# pmac_acm_secure register map
Vendor: Texas Instruments
Peripheral module from a debugger description file (folder CC35X1E).
Registers are 32-bit, access per field, reset 0x0 unless marked. A register's access mark holds for its fields unless they carry their own. Offsets are as the file gives them; lines under a group give offsets from that group; [hi:lo] are bit positions; {n}, {i} and the like mark numbered series; 'fields as' and 'values as' point back to an identical list; <NAME> marks a mode.

## pmac_acm_secure
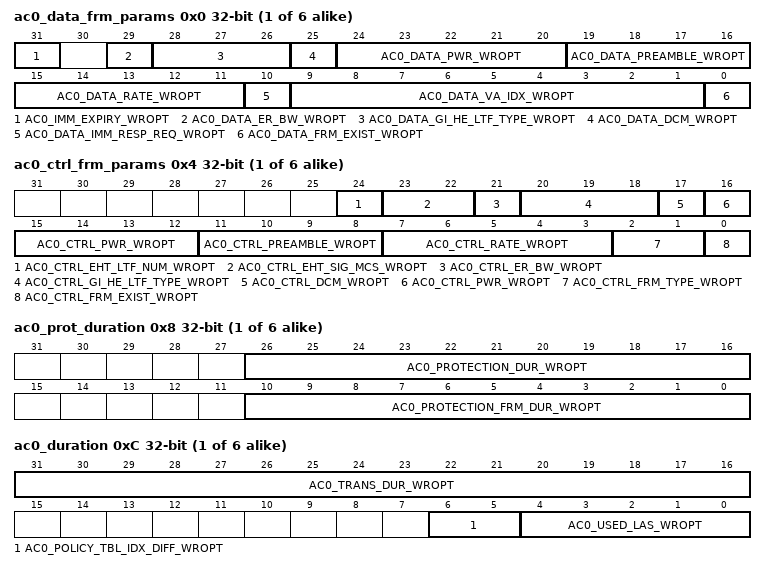
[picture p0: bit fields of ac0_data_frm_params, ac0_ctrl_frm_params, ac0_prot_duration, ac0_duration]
{0x0+0x30*i} ac{i}_data_frm_params (i=0..5) — current data frame params as set by the tx candidate.
  [31] AC{i}_IMM_EXPIRY_WROPT rw
  [29] AC{i}_DATA_ER_BW_WROPT rw
  [28:26] AC{i}_DATA_GI_HE_LTF_TYPE_WROPT rw
  [25] AC{i}_DATA_DCM_WROPT rw
  [24:20] AC{i}_DATA_PWR_WROPT rw — data frame power.
  [19:16] AC{i}_DATA_PREAMBLE_WROPT rw — data frame preamble. phy coding.
  [15:11] AC{i}_DATA_RATE_WROPT rw — data frame rate. pmac coding (not PHY coding)
  [10] AC{i}_DATA_IMM_RESP_REQ_WROPT rw — Immediate response is expected.
  [9:1] AC{i}_DATA_VA_IDX_WROPT rw — data frame's Virtual address index (frame at the head of the queue)
  [0] AC{i}_DATA_FRM_EXIST_WROPT rw — indication that the data AC regs are of a valid frame. asserte by candidate.
{0x4+0x30*i} ac{i}_ctrl_frm_params (i=0..5)
  [24] AC{i}_CTRL_EHT_LTF_NUM_WROPT rw
  [23:22] AC{i}_CTRL_EHT_SIG_MCS_WROPT rw
  [21] AC{i}_CTRL_ER_BW_WROPT rw
  [20:18] AC{i}_CTRL_GI_HE_LTF_TYPE_WROPT rw
  [17] AC{i}_CTRL_DCM_WROPT rw
  [16:12] AC{i}_CTRL_PWR_WROPT rw — control frame power.
  [11:8] AC{i}_CTRL_PREAMBLE_WROPT rw — control frame preamble (phy coding)
  [7:3] AC{i}_CTRL_RATE_WROPT rw — control frame rate. pmac coding (not PHY coding)
  [2:1] AC{i}_CTRL_FRM_TYPE_WROPT rw — control frame type: 0 - RTS, 1 - CTS, 2 - CF_END
  [0] AC{i}_CTRL_FRM_EXIST_WROPT rw — control frame exist - for RTS/CTS, if this bit is asserted, current transmission will be of the protection frame. for cf_end, transmission depands on remaining time and data frame existence.
{0x8+0x30*i} ac{i}_prot_duration (i=0..5)
  [26:16] AC{i}_PROTECTION_DUR_WROPT rw — entire protection duration CTS+SIFS or RTS+SIFS+CTS+SIFS. field is ignored in burst case.
  [10:0] AC{i}_PROTECTION_FRM_DUR_WROPT rw — protection frame duration - CTS, RTS or CF_END
{0xC+0x30*i} ac{i}_duration (i=0..5)
  [31:16] AC{i}_TRANS_DUR_WROPT rw — total transaction duration - protection + data frame and Imm response
  [6:5] AC{i}_POLICY_TBL_IDX_DIFF_WROPT rw — Indication on wither LAS state was overriden by get_rate nad wither to easier or harder state 00 - same state 01 - easier state 10 - harder state
  [4:0] AC{i}_USED_LAS_WROPT rw — Used LAS (Link adaptation state).
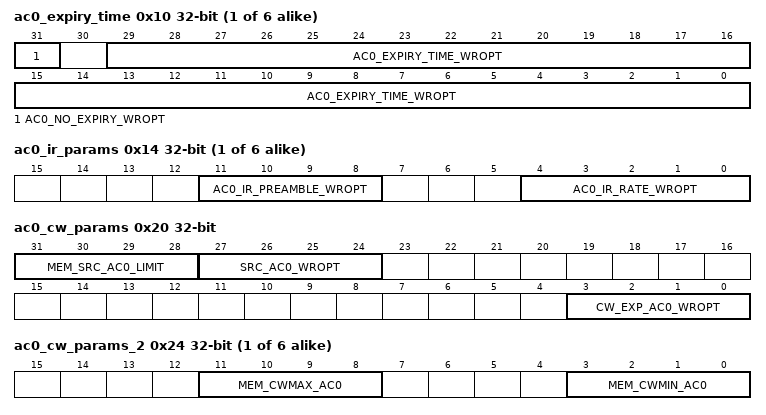
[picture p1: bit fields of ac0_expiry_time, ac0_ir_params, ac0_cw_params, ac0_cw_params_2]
{0x10+0x30*i} ac{i}_expiry_time (i=0..5)
  [31] AC{i}_NO_EXPIRY_WROPT rw
  [29:0] AC{i}_EXPIRY_TIME_WROPT rw — expiry time in micro seconds
{0x14+0x30*i} ac{i}_ir_params (i=0..5)
  [11:8] AC{i}_IR_PREAMBLE_WROPT rw — Imm response preamble (PHY coding)
  [4:0] AC{i}_IR_RATE_WROPT rw — Imm response rate (pmac coding)
0x20 ac0_cw_params reset not defined
  [31:28] MEM_SRC_AC0_LIMIT rw — station retries counter limit. src clears on values greater then this limit.
  [27:24] SRC_AC0_WROPT rw — station retries counter.
  [3:0] CW_EXP_AC0_WROPT rw — CW exponent for AC0
{0x24+0x30*i} ac{i}_cw_params_2 reset not defined (i=0..5)
  [11:8] MEM_CWMAX_AC{i} rw — cw max exponent
  [3:0] MEM_CWMIN_AC{i} rw — CW min exponent
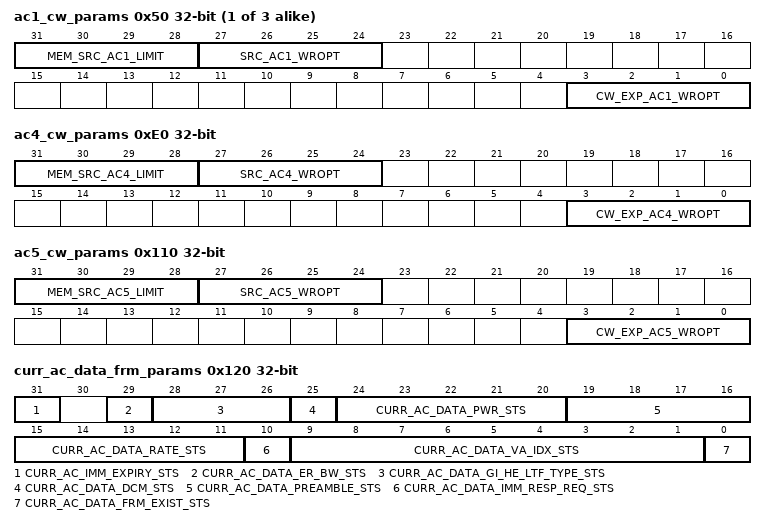
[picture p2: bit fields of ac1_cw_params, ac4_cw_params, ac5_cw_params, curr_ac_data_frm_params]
{0x20+0x30*i} ac{i}_cw_params reset not defined (i=1..3)
  [31:28] MEM_SRC_AC{i}_LIMIT rw
  [27:24] SRC_AC{i}_WROPT rw — station retries counter
  [3:0] CW_EXP_AC{i}_WROPT rw — CW exponent for AC{i}
0xE0 ac4_cw_params reset not defined
  [31:28] MEM_SRC_AC4_LIMIT rw
  [27:24] SRC_AC4_WROPT rw — station retries coutner
  [3:0] CW_EXP_AC4_WROPT rw — CW exponent for AC4
0x110 ac5_cw_params reset not defined
  [31:28] MEM_SRC_AC5_LIMIT rw
  [27:24] SRC_AC5_WROPT rw — station retries counter
  [3:0] CW_EXP_AC5_WROPT rw — CW mask for AC5
0x120 curr_ac_data_frm_params ro — current data frame params as set by the tx candidate.
  [31] CURR_AC_IMM_EXPIRY_STS
  [29] CURR_AC_DATA_ER_BW_STS
  [28:26] CURR_AC_DATA_GI_HE_LTF_TYPE_STS
  [25] CURR_AC_DATA_DCM_STS
  [24:20] CURR_AC_DATA_PWR_STS — data frame power.
  [19:16] CURR_AC_DATA_PREAMBLE_STS — data frame preamble. phy coding.
  [15:11] CURR_AC_DATA_RATE_STS — data frame rate. pmac coding (not PHY coding)
  [10] CURR_AC_DATA_IMM_RESP_REQ_STS — Immediate response is expected.
  [9:1] CURR_AC_DATA_VA_IDX_STS — data frame's Virtual address index (frame at the head of the queue)
  [0] CURR_AC_DATA_FRM_EXIST_STS — indication that the data AC regs are of a valid frame. asserte by candidate.
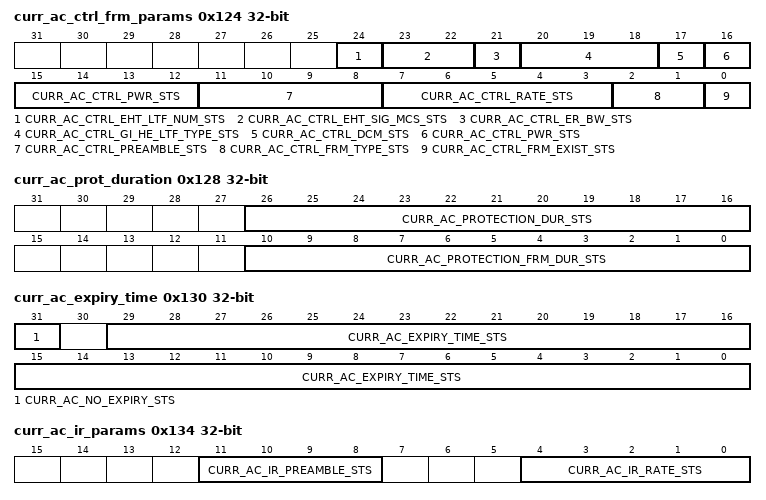
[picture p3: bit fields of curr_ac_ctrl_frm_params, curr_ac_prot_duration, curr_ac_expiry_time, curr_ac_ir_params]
0x124 curr_ac_ctrl_frm_params ro
  [24] CURR_AC_CTRL_EHT_LTF_NUM_STS
  [23:22] CURR_AC_CTRL_EHT_SIG_MCS_STS
  [21] CURR_AC_CTRL_ER_BW_STS
  [20:18] CURR_AC_CTRL_GI_HE_LTF_TYPE_STS
  [17] CURR_AC_CTRL_DCM_STS — data frame DCM (Dual Code Modulation).
  [16:12] CURR_AC_CTRL_PWR_STS — control frame power.
  [11:8] CURR_AC_CTRL_PREAMBLE_STS — control frame preamble (phy coding)
  [7:3] CURR_AC_CTRL_RATE_STS — control frame rate. pmac coding (not PHY coding)
  [2:1] CURR_AC_CTRL_FRM_TYPE_STS — control frame type: 0 - RTS, 1 - CTS, 2 - CF_END
  [0] CURR_AC_CTRL_FRM_EXIST_STS — control frame exist - for RTS/CTS, if this bit is asserted, current transmission will be of the protection frame. for cf_end, transmission depands on remaining time and data frame existence.
0x128 curr_ac_prot_duration ro
  [26:16] CURR_AC_PROTECTION_DUR_STS — entire protection duration CTS+SIFS or RTS+SIFS+CTS+SIFS. field is ignored in burst case.
  [10:0] CURR_AC_PROTECTION_FRM_DUR_STS — protection frame duration - CTS, RTS or CF_END
0x12C curr_ac_duration ro
  [31:16] CURR_AC_TRANS_DUR_STS — total transaction duration - protection + data frame and Imm response
0x130 curr_ac_expiry_time ro
  [31] CURR_AC_NO_EXPIRY_STS
  [29:0] CURR_AC_EXPIRY_TIME_STS — expiry time in micro seconds
0x134 curr_ac_ir_params ro
  [11:8] CURR_AC_IR_PREAMBLE_STS — Imm response preamble (PHY coding)
  [4:0] CURR_AC_IR_RATE_STS — Imm response rate (pmac coding)
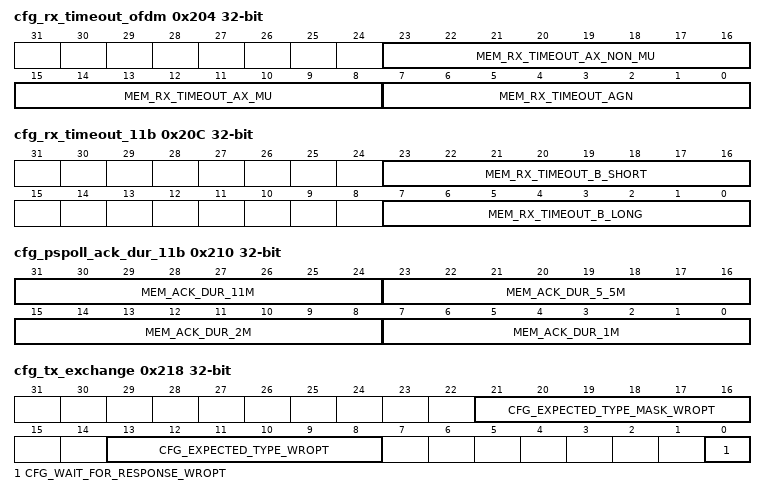
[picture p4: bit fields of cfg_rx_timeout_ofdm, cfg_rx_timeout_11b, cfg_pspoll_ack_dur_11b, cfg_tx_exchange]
0x204 cfg_rx_timeout_ofdm
  [23:16] MEM_RX_TIMEOUT_AX_NON_MU rw — Rx timeout for HE non MU use cases (HE_SU, HE-ER-SU, HE-TB).
  [15:8] MEM_RX_TIMEOUT_AX_MU rw — Rx timeout for HE_MU use case.
  [7:0] MEM_RX_TIMEOUT_AGN rw — Rx timeout for legacy, HT-MM and HT-GF use cases.
0x20C cfg_rx_timeout_11b
  [23:16] MEM_RX_TIMEOUT_B_SHORT rw — Rx timeout for 11b short use case.
  [7:0] MEM_RX_TIMEOUT_B_LONG rw — Rx timeout for 11b long use case.
0x210 cfg_pspoll_ack_dur_11b rw reset not defined — claculations do not include the preamble - it is set by HW according to current incoming frame.
  [31:24] MEM_ACK_DUR_11M — sifs + ack duration for 11mbps
  [23:16] MEM_ACK_DUR_5_5M — sifs + ack duration for 5.5mbps
  [15:8] MEM_ACK_DUR_2M — sifs + ack duration for 2mbps
  [7:0] MEM_ACK_DUR_1M — sifs + ack duration for 1mbps
0x214 cfg_pspoll_ack_dur_ofdm reset not defined
  [7:0] MEM_ACK_DUR_6_OFDM rw — sifs + ack duration at 6mbps
0x218 cfg_tx_exchange
  [21:16] CFG_EXPECTED_TYPE_MASK_WROPT rw, [13:8] CFG_EXPECTED_TYPE_WROPT rw, [0] CFG_WAIT_FOR_RESPONSE_WROPT rw
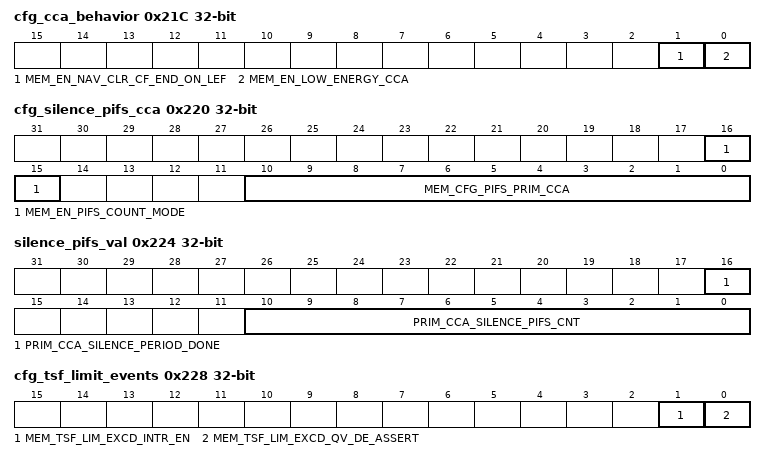
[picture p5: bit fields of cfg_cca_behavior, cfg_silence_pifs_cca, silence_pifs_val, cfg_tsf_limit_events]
0x21C cfg_cca_behavior reset not defined
  [1] MEM_EN_NAV_CLR_CF_END_ON_LEF rw — when set, low energy cf_end frame clears the NAV . when cleared lef cf_end is ignored with regards to NAV like all rx lef frames.
  [0] MEM_EN_LOW_ENERGY_CCA rw — when set, if qual_cca is high while phy_cca is low, force qual_cca to as well and use RIP to prevent starting tranmission during currently received rx
0x220 cfg_silence_pifs_cca reset not defined — PIFS counter for CCA
  [16:15] MEM_EN_PIFS_COUNT_MODE rw — 00: disabled. force the status to silence period done. 01: single count. counter counts until cca_idle time and locks until disabled. 10: continuous count cca aware- clear the timer on every cca_busy 11: continuous count cca un-aware - on cca fall, count without stopping until expired.
  [10:0] MEM_CFG_PIFS_PRIM_CCA rw — PIFS duration for primary pifs counter. count is in 20MHz resolution (50ns)
0x224 silence_pifs_val ro
  [16] PRIM_CCA_SILENCE_PERIOD_DONE
  [10:0] PRIM_CCA_SILENCE_PIFS_CNT — current value of the silnce pifs counter
0x228 cfg_tsf_limit_events
  [1] MEM_TSF_LIM_EXCD_INTR_EN rw — when set, if any AC's tsf limit was crossed, assert an IRQ to SW.
  [0] MEM_TSF_LIM_EXCD_QV_DE_ASSERT rw — when set, it any AC's TSF limit was crossed, create a qv de_assert request for that AC
0x22C tx_nav
  [14:0] TX_NAV_WROPT rw — tx nav counter. set by HW to 'duration' on tx_trigger. cleared when frames markd by SW to clear the tx_nav. counts in usec resolution
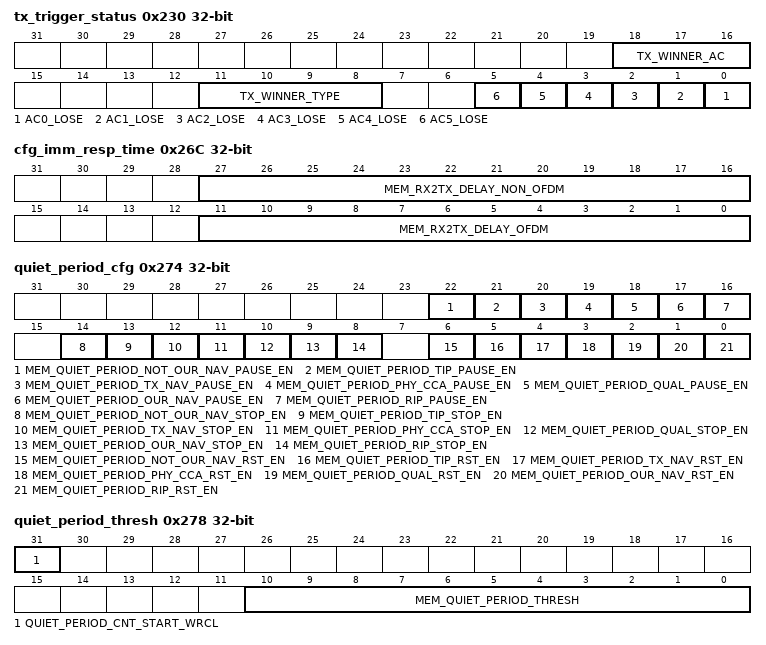
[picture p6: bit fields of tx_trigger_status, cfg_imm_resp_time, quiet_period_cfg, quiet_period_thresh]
0x230 tx_trigger_status ro
  [18:16] TX_WINNER_AC — latched value of the last AC winner (AC0-AC5). this may be used to understand in burst/cf_end which is the originating AC
  [11:8] TX_WINNER_TYPE — 0: EDCA 1: Immidiate response 2: Burst 3: Cf_end after rx time out 4: Trigger-Based data 5: Trigger-Based immidiate response 6: Trigger-Based report
  [n] AC{n}_LOSE (n=0..5) — ac lost in EDCA internal collision
0x234 tx_delay_cnt reset not defined
  [11:0] MEM_TXDELAY_CNT rw
{0x238+8i} tsf_start_ac{i} rw (i=0..5) — The access mechanism is active when TSF bigger then TSF START. In case that TSF start is zero, then the above condition is true, so the access mechanim is active.
  [31:0] MEM_TSF_START_VALUE_AC{i}
{0x23C+8i} tsf_end_ac{i} rw (i=0..5) — It contains the low bits of the END TSF value. The access mechanism is active when TSF smaller then TSF END. In case that TSF start is zero, then the above condition is true, so the access mechanim is active.
  [31:0] MEM_TSF_END_VALUE_AC{i}
0x268 cfg_burst_thresh reset not defined
  [6:0] MEM_ENOUGH_TIME_CF_END_EXT rw — number of usec to add to the 'enough time for cf_end' indication from access to tx manager. this allows to avoid transmitting cf_end if txop is almost exhausted anyway.
0x26C cfg_imm_resp_time reset not defined
  [27:16] MEM_RX2TX_DELAY_NON_OFDM rw — delay in 40MHz cycles to count for imm response after rx (sifs) for 11b rx
  [11:0] MEM_RX2TX_DELAY_OFDM rw — delay in 40MHz cycles to count for imm response after rx (sifs) for ofdm rx
0x270 access_spare_reg rw reset 0xFFFF
  [31:0] MEM_ACCESS_SPARE_REG
0x274 quiet_period_cfg
  [22] MEM_QUIET_PERIOD_NOT_OUR_NAV_PAUSE_EN rw — when set, counter is paused on NAV
  [21] MEM_QUIET_PERIOD_TIP_PAUSE_EN rw — when set, counter is paused on TIP | TXIP
  [20] MEM_QUIET_PERIOD_TX_NAV_PAUSE_EN rw — when set, counter is paused on TX_NAV
  [19] MEM_QUIET_PERIOD_PHY_CCA_PAUSE_EN rw — when set, counter is paused on PHY_CCA (from phy, no MAC overrides)
  [18] MEM_QUIET_PERIOD_QUAL_PAUSE_EN rw — when set, counter is paused on QUAL_CCA (from phy, no MAC overrides)
  [17] MEM_QUIET_PERIOD_OUR_NAV_PAUSE_EN rw — when set, counter is paused on NAV
  [16] MEM_QUIET_PERIOD_RIP_PAUSE_EN rw — when set, counter is paused on RIP | RXIP
  [14] MEM_QUIET_PERIOD_NOT_OUR_NAV_STOP_EN rw — when set, counter is paused on NAV
  [13] MEM_QUIET_PERIOD_TIP_STOP_EN rw — when set, counter is paused on TIP | TXIP
  [12] MEM_QUIET_PERIOD_TX_NAV_STOP_EN rw — when set, counter is paused on TX_NAV
  [11] MEM_QUIET_PERIOD_PHY_CCA_STOP_EN rw — when set, counter is paused on PHY_CCA (from phy, no MAC overrides)
  [10] MEM_QUIET_PERIOD_QUAL_STOP_EN rw — when set, counter is paused on QUAL_CCA (from phy, no MAC overrides)
  [9] MEM_QUIET_PERIOD_OUR_NAV_STOP_EN rw — when set, counter is paused on NAV
  [8] MEM_QUIET_PERIOD_RIP_STOP_EN rw — when set, counter is paused on RIP | RXIP
  [6] MEM_QUIET_PERIOD_NOT_OUR_NAV_RST_EN rw — when set, counter is reset on NAV
  [5] MEM_QUIET_PERIOD_TIP_RST_EN rw — when set, counter is reset on TIP | TXIP
  [4] MEM_QUIET_PERIOD_TX_NAV_RST_EN rw — when set, counter is reset on TX_NAV
  [3] MEM_QUIET_PERIOD_PHY_CCA_RST_EN rw — when set, counter is reset on PHY_CCA (from phy, no MAC overrides)
  [2] MEM_QUIET_PERIOD_QUAL_RST_EN rw — when set, counter is reset on QUAL_CCA (from phy, no MAC overrides)
  [1] MEM_QUIET_PERIOD_OUR_NAV_RST_EN rw — when set, counter is reset on NAV
  [0] MEM_QUIET_PERIOD_RIP_RST_EN rw — when set, counter is reset on RIP | RXIP
0x278 quiet_period_thresh
  [31] QUIET_PERIOD_CNT_START_WRCL wo — counter kick, wr only/self clearing
  [10:0] MEM_QUIET_PERIOD_THRESH rw — counter threshold in 32usec resolution. Threshold should not be modified during counter operation. in order to change, counter need to be halted and re-configured
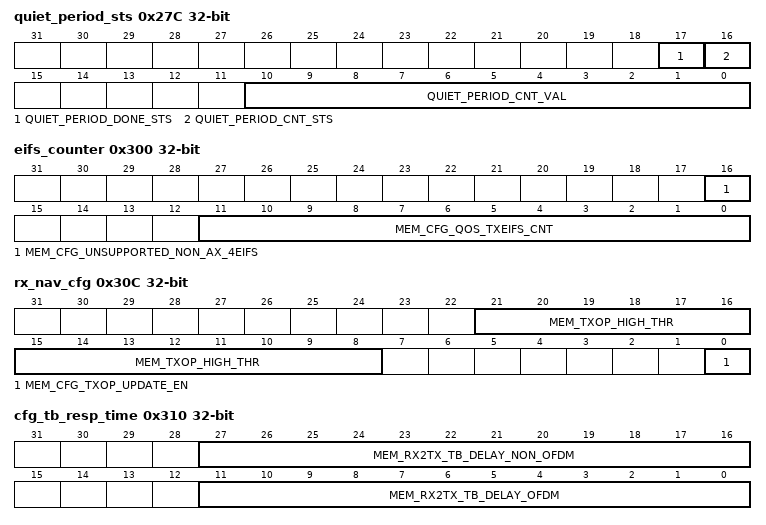
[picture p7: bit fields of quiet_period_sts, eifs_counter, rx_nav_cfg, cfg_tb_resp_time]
0x27C quiet_period_sts ro
  [17] QUIET_PERIOD_DONE_STS — when read as 1, counter has already expired and asserted the interrupt.
  [16] QUIET_PERIOD_CNT_STS — when read as 1, counter is during count (even if paused/cleared by the HW)
  [10:0] QUIET_PERIOD_CNT_VAL — current counter value
0x280 quiet_period_cnt_stop
  [0] QUIET_PERIOD_CNT_STOP_WRCL wo — writing 1 to this bit will stop the counter.
{0x284+0x14*i} backoff_timer_ac{i}_reg (i=0..3) — Back-off counter for AC {i} (BACKOFF_TIMER_AC{i}_REG)
  [15:0] MEM_BACKOFF_TIMER_AC{i}_WROPT rw — Random back-off timer. Latch with random value between 0 to CW[AC] count down to 0 every time AIFS[AC] timeout out and slot timer reaches zero.
{0x288+0x14*i} copy_backoff_timer_ac{i}_reg (i=0..3) — Copy back-off timer AC{i} (COPY_BACKOFF_TIMER_AC{i}_REG)
  [15:0] MEM_COPY_BACKOFF_TIMER_AC{i}_WROPT rw — Random back-off timer for AC{i}. Used for interference fix. Latch stores back-off value for AC{i} when input/tx CCA indicate medium busy.
0x28C rng_ac0 rw reset 0xAAAA5555
  [31:0] MEM_RNG_AC0_WROPT — Initial value for Ramdom Number Generator for this AC
0x290 ac0_tx_aifs_cfg_reg reset 0x3D03D — Slot Count (ACM_IFS_CFG1)
  [11:0] MEM_CFG_TXAIFS0_CNT rw — AC0 AIFS counter size in micro seconds
{0x294+0x14*i} ac{i}_tx_aifs_timer_reg (i=0..5) — Current value of AIFS timer for this ac
  [11:0] MEM_TXAIFS{i}_TIMER_WROPT rw — Current value of AIFS timer in usec.;It_s a up counter. this value get compared with ACM_TX_AIFS[n] to start back-off countdown.
0x2A0 rng_ac1 rw reset 0xAA55AA55
  [31:0] MEM_RNG_AC1_WROPT — Initial value for Ramdom Number Generator for this AC
0x2A4 ac1_tx_aifs_cfg_reg reset 0x1D01D — Transmit AIFS1 timer (AC1_TX_AIFS_CFG_REG)
  [11:0] MEM_CFG_TXAIFS1_CNT rw — TxAIFS1/EIFS timer in usec. ;Configured with the value obtained from EDCA parameter from QAP. No byte access must write entire field once.
0x2B4 rng_ac2 rw reset 0x55AA55AA
  [31:0] MEM_RNG_AC2_WROPT — Initial value for Ramdom Number Generator for this AC
0x2B8 ac2_tx_aifs_cfg_reg — Transmit AIFS2 timer (AC2_TX_AIFS_CFG_REG)
  [11:0] MEM_CFG_TXAIFS2_CNT rw — TxAIFS2/EIFS timer in usec. ;Configured with the value obtained from EDCA parameter from QAP.;No byte access must write entire field once.
0x2C8 rng_ac3 rw reset 0x5A5A5A5A
  [31:0] MEM_RNG_AC3_WROPT — Initial value for Ramdom Number Generator for this AC
0x2CC ac3_tx_aifs_cfg_reg reset 0x15015 — Transmit AIFS3 timer (AC3_TX_AIFS_CFG_REG)
  [11:0] MEM_CFG_TXAIFS3_CNT rw — TxAIFS3/EIFS timer in usec. ;Configured with the value obtained from EDCA parameter from QAP.;No byte access must write entire field once.
0x2D4 backoff_timer_ac4_reg
  [14:0] MEM_BACKOFF_TIMER_AC4_WROPT rw — Backoff for AC4 mechanism
0x2D8 copy_of_backoff_timer_ac4_reg
  [14:0] MEM_COPY_BACKOFF_TIMER_AC4_WROPT rw — copy Backoff for AC4 mechanism
0x2DC rng_ac4 rw reset 0xAAAA5555
  [31:0] MEM_RNG_AC4_WROPT — Initial value for Ramdom Number Generator for this AC4
0x2E0 ac4_tx_aifs_cfg_reg
  [11:0] MEM_CFG_TXAIFS4_CNT rw — aifs value for AC4
0x2E8 backoff_timer_ac5_reg
  [14:0] MEM_BACKOFF_TIMER_AC5_WROPT rw — Backoff for AC5 mechanism
0x2EC copy_of_backoff_timer_ac5_reg
  [14:0] MEM_COPY_BACKOFF_TIMER_AC5_WROPT rw — copy Backoff for AC4 mechanism
0x2F0 rng_ac5 rw reset 0xAAAA5555
  [31:0] MEM_RNG_AC5_WROPT — Initial value for Ramdom Number Generator for this AC5
0x2F4 ac5_tx_aifs_cfg_reg
  [11:0] MEM_CFG_TXAIFS5_CNT rw — aifs value for AC5
0x2FC acm_tx_eifs_timer_reg — Current value of EIFS counter (ACM_TX_EIFS_TIMER_REG)
  [11:0] MEM_TXEIFS_TIMER_WROPT rw — Current value of EIFS timer in usec.
0x300 eifs_counter — EIFS-DIFS value configuration for Meduim access backoff usage.
  [16] MEM_CFG_UNSUPPORTED_NON_AX_4EIFS rw — For: Received frames which are not of AX type, and unsupported (meaning there is not a valid PHY Header): if '1' (default) - set EIFS timer if '0' - don't set EIFS timer
  [11:0] MEM_CFG_QOS_TXEIFS_CNT rw — EIFS counter configuration value
0x304 our_nav — Network allocation Vector (NAV)* (1) OUR NAV / INTRA BSS NAV
  [15:0] OUR_NAV_WROPT rw — Network allocation vector (virtual carrier sense). Loaded. cleared and decremented according to 802.11 spec. When non-zero. normal transmit operations will be prevented. (usec) ) (No byte access. must write as 16 bit register). our_bss: Protection from frames transmitted by STAs within its BSS, i.e., intra-BSS,
0x308 not_our_nav — Network allocation Vector (NAV)* (2) NOT OUR NAV / INTER BSS NAV / BASIC NAV
  [15:0] NOT_OUR_NAV_WROPT rw — Network allocation vector (virtual carrier sense). Loaded. cleared and decremented according to 802.11 spec. When non-zero. normal transmit operations will be prevented. (usec) ) (No byte access. must write as 16 bit register). Network allocation vector (virtual carrier sense). Loaded. cleared and decremented according to 802.11 spec. When non-zero. normal transmit operations will be prevented. (usec) ) (No byte access. must write as 16 bit register). not_our_bss: Avoid interference from frames transmitted by STAs in a neighboring BSS, i.e., inter-BSS.
0x30C rx_nav_cfg reset not defined — Configuration controls for dual NAVs feature
  [21:8] MEM_TXOP_HIGH_THR rw — If TXOP field is greater than this THR, don't update NAVs with TXOP
  [0] MEM_CFG_TXOP_UPDATE_EN rw — if ='0': Disable ability to update NAVs by TXOP field from PHY-Header
0x310 cfg_tb_resp_time reset not defined
  [27:16] MEM_RX2TX_TB_DELAY_NON_OFDM rw — delay in 40MHz cycles to count for response after trigger frame (sifs) for 11b rx
  [11:0] MEM_RX2TX_TB_DELAY_OFDM rw — delay in 40MHz cycles to count for response after trigger frame (sifs) for ofdm rx
0x314 cfg_tb_cs_time reset not defined
  [11:0] MEM_TB_CS_DELAY_CNT rw — Delay in 40MHz cycles to count when to start CS detection during SIFS period.
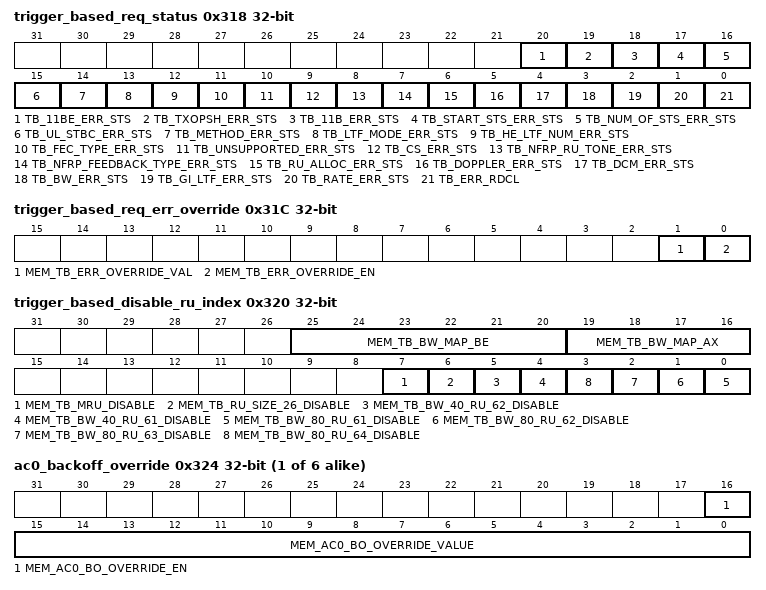
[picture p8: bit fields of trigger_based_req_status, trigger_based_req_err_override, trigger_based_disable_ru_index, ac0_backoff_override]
0x318 trigger_based_req_status ro reset not defined
  [20] TB_11BE_ERR_STS — Trigger-Based request with 11.BE (=EHT=WiFi7) packet error. Clear on TB_ERR_RDCL read.
  [19] TB_TXOPSH_ERR_STS — Trigger-Based MU-RTS TXOP-Sharing request error. Clear on TB_ERR_RDCL read.
  [18] TB_11B_ERR_STS — Trigger-Based request with 11B packet error. Clear on TB_ERR_RDCL read.
  [17] TB_START_STS_ERR_STS — Trigger-Based request with Starting SS error. Clear on TB_ERR_RDCL read.
  [16] TB_NUM_OF_STS_ERR_STS — Trigger-Based request with Numer of SS error. Clear on TB_ERR_RDCL read.
  [15] TB_UL_STBC_ERR_STS — Trigger-Based request with STBC error. Clear on TB_ERR_RDCL read.
  [14] TB_METHOD_ERR_STS — Trigger-Based request with TB method error. Clear on TB_ERR_RDCL read.
  [13] TB_LTF_MODE_ERR_STS — Trigger-Based request with LTF Mode error. Clear on TB_ERR_RDCL read.
  [12] TB_HE_LTF_NUM_ERR_STS — Trigger-Based request with HE LTF NUM error. Clear on TB_ERR_RDCL read.
  [11] TB_FEC_TYPE_ERR_STS — Trigger-Based request with FEC type error. Clear on TB_ERR_RDCL read.
  [10] TB_UNSUPPORTED_ERR_STS — Trigger-Based request with unsupported type error. Clear on TB_ERR_RDCL read. The list of unsupported trigger types is determined by TRIGGER_BASED_TYPE_MASK configuration.
  [9] TB_CS_ERR_STS — Trigger-Based request with CS error. Clear on TB_ERR_RDCL read.
  [8] TB_NFRP_RU_TONE_ERR_STS — NFRP Trigger-Based request with RU tone error. Clear on TB_ERR_RDCL read.
  [7] TB_NFRP_FEEDBACK_TYPE_ERR_STS — NFRP Trigger-Based request with feedback type error. Clear on TB_ERR_RDCL read.
  [6] TB_RU_ALLOC_ERR_STS — Trigger-Based request with RU allocation error. Clear on TB_ERR_RDCL read.
  [5] TB_DOPPLER_ERR_STS — Trigger-Based request with doppler error. Clear on TB_ERR_RDCL read.
  [4] TB_DCM_ERR_STS — Trigger-Based request with DCM error. Clear on TB_ERR_RDCL read.
  [3] TB_BW_ERR_STS — Trigger-Based request with bandwidth error. Clear on TB_ERR_RDCL read.
  [2] TB_GI_LTF_ERR_STS — Trigger-Based request with GI_LTF field error. Clear on TB_ERR_RDCL read.
  [1] TB_RATE_ERR_STS — Trigger-Based request with rate error. Clear on TB_ERR_RDCL read.
  [0] TB_ERR_RDCL — Trigger-Based request general error. Bits [8:1] holds the reason for the error. Clear on read.
0x31C trigger_based_req_err_override reset not defined
  [1] MEM_TB_ERR_OVERRIDE_VAL rw — Override value for Trigger-Based request error decision.
  [0] MEM_TB_ERR_OVERRIDE_EN rw — Bypass HW error decision for Trigger-Based request. The override value is set by MEM_TB_ERR_OVERRIDE_VAL register
0x320 trigger_based_disable_ru_index reset not defined — Disable RU index 61-64 support Disable RU Size of 26 option Disable MRU as default option TB_BW MAPS for AX and BW
  [25:20] MEM_TB_BW_MAP_BE rw — TB_BW MAP to define which BW is Allowed for BE (=EHT=WjFi7) bit[0] - 20/20MHz (Default Allowed) bit[1] - 20/40MHz (Default Not Allowed) bit[2] - 20/80MHz (Default Not Allowed) bit[3] - 20/160MHz (Default Not Allowed) bit[4] - 20/320MHz-1 (Default Not Allowed) bit[5] - 20/320MHz-2 (Default Not Allowed)
  [19:16] MEM_TB_BW_MAP_AX rw — TB_BW MAP to define wich BW is Allowed bit[0] - 20/20MHz (Default Allowed) bit[1] - 20/40MHz (Default Allowed) bit[2] - 20/80MHz (Default Allowed) bit[3] - 20/160MHz (Default Not Allowed)
  [7] MEM_TB_MRU_DISABLE rw — Disable EHT MRU TB type for all bandwidthes
  [6] MEM_TB_RU_SIZE_26_DISABLE rw — Disable RU Size 26 support in all bandwidthes
  [5] MEM_TB_BW_40_RU_62_DISABLE rw — Disable RU index 62 support in 40MHz bandwidth
  [4] MEM_TB_BW_40_RU_61_DISABLE rw — Disable RU index 61 support in 40MHz bandwidth
  [n-61] MEM_TB_BW_80_RU_{n}_DISABLE rw (n=61..64) — Disable RU index {n} support in 80MHz bandwidth
{0x324+4i} ac{i}_backoff_override reset not defined (i=0..5)
  [16] MEM_AC{i}_BO_OVERRIDE_EN rw — Enable AC{i} backoff override
  [15:0] MEM_AC{i}_BO_OVERRIDE_VALUE rw — AC{i} backoff override value
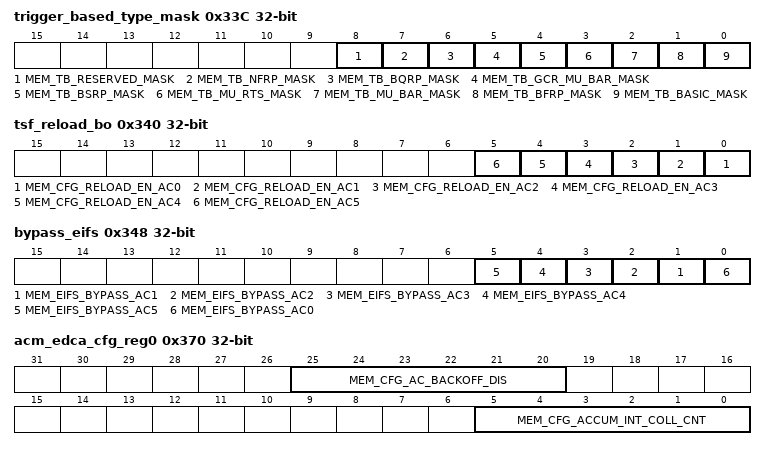
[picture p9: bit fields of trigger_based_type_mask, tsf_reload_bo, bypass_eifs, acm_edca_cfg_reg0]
0x33C trigger_based_type_mask reset not defined — Disable RU index 61-64 support
  [8] MEM_TB_RESERVED_MASK rw — Mask reserved trigger frame (types 8-15)
  [7] MEM_TB_NFRP_MASK rw — Mask NFRP (NDP Feedback Report Poll) trigger frame
  [6] MEM_TB_BQRP_MASK rw — Mask BQRP (Bandwidth Query Report Poll) trigger frame
  [5] MEM_TB_GCR_MU_BAR_MASK rw — Mask GCR MU-BAR trigger frame
  [4] MEM_TB_BSRP_MASK rw — Mask BSRP (Buffer Status Report Poll) trigger frame
  [3] MEM_TB_MU_RTS_MASK rw — Mask MU-RTS trigger frame
  [2] MEM_TB_MU_BAR_MASK rw — Mask MU-BAR trigger frame
  [1] MEM_TB_BFRP_MASK rw — Mask BFRP (Beamforming Report Poll) trigger frame
  [0] MEM_TB_BASIC_MASK rw — Mask basic trigger frame
0x340 tsf_reload_bo reset not defined
  [n] MEM_CFG_RELOAD_EN_AC{n} rw (n=0..5) — when set, when crossing TSF limit, BO will be reloaded
0x344 txsifs_timer reset 0xF00F0 — Transmit SIFS Timer (TXSIFS_TIMER)
  [11:0] TXSIFS_TIMER_WROPT rw — TxSIFS protocol timer. 0 if TxSIFS time expired. (usec) (No byte access. must write as 32 bit register).
0x348 bypass_eifs — when bit [n] is 1. the related ac ignore eifs: n=0: ac0 n=1: ac1 n=2: ac2 n=3: ac3 n=4: tsf1 n=5: tsf2
  [n] MEM_EIFS_BYPASS_AC{n} rw (n=1..5)
  [0] MEM_EIFS_BYPASS_AC0 rw — see above
0x34C slot_timer ro reset 0x320320 — Slot Timer (SLOT_TIMER)
  [11:0] SLOT_TIMER — Slot timer. Continuously counts down the slot time while the medium is idle and the TxDIFS/EIFS time has expired. (usec)
0x354 tsf_l ro — TSF Low (TSF_L)
  [31:0] TSF_31_0_WRDCL — Low 32 bits of station_s TSF timer. (usec) ) (No byte access. must write as 32 bit register).;This register must be read before _H
0x358 tsf_h rw — TSF High (TSF_H)
  [31:0] HOLD_REG_WROPT — High 32 bits of station_s TSF timer. (usec) ) (No byte access. must write as 32 bit register).;This register must be written to before _L
0x35C med_usage ro — Medium Usage (MED_USAGE)*
  [31:0] MED_USAGE_31_0_RDCL — Incremented every usec when medium is busy (physical or virtual carrier sense). Automatically cleared upon read.
0x360 med_usage_tm ro — Medium Usage Time (MED_USAGE_TM)
  [31:0] HOLD_REG_31_0 — Number of usec sense MED_USAGE was last read. (Note: These 2 registers can give a general feel for the utilization of the network. Must read MED_USAGE_TM prior to reading MED_USAGE.)
0x364 dtim_cnt — DTIM Counter (DTIM_CNT)
  [7:0] DTIM_CNT_WROPT rw — Current DTIM count for BSS. ) (No byte access. must write as 32-bit register).
0x368 prb_dly ro — Probe Delay Time (PRB_DLY)
  [9:0] PRB_DLY_TIMER — Current value of probe delay timer. Loaded with probe delay time upon clearing ENABLE [0] or ENABLE [1] or setting HW_DOZE. Prevents normal transmit until a frame is received or reaches zero.
0x36C cfg_acm — QOS Auto ACK Disable (CFG_ACM)
  [0] MEM_CFG_NAV_QOS_EN rw
0x370 acm_edca_cfg_reg0 — EDCA Configuration 0 (ACM_EDCA_CFG_REG0)
  [25:20] MEM_CFG_AC_BACKOFF_DIS rw — No back-off: if this bit is set do not follow back-off. start transmission after AIFS;Bit [23] _ for AC3;Bit [22] _ for AC2;Bit [21] _ for AC1;Bit [20] _ for AC0;OPTIONAL: Bits 23.22.21 must be left at default
  [5:0] MEM_CFG_ACCUM_INT_COLL_CNT rw — Accumulate internal collision count for AC.;[0] _ AC0;[1] _ AC1;[2] _ AC2;[3] _ AC3;when set internal collision count get accumulated and doesn_t get cleared when particular AC wins contention. For debug.;OPTIONAL: Must be left at default
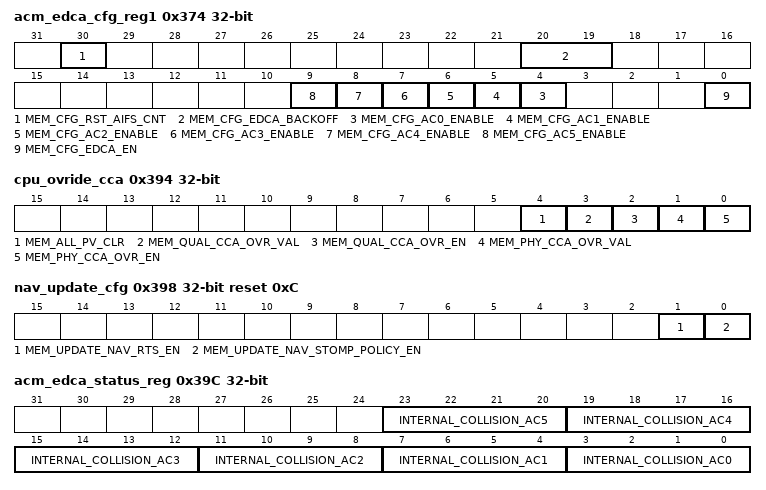
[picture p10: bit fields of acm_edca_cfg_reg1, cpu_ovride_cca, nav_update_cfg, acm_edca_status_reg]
0x374 acm_edca_cfg_reg1 reset not defined — EDCA Configuration 1 (ACM_EDCA_CFG_REG1)
  [30] MEM_CFG_RST_AIFS_CNT rw — Reset AIFS counter;Self-clearing but. If set clears AIFS timer.
  [20:19] MEM_CFG_EDCA_BACKOFF rw — EDCA back-off configuration;00 _ evoke back-off for all Acs when last transmission from any AC fails.;01 _ evoke back-off for other Acs only after expiry of NAV set by previously failed transmission.;1x _ evoke back-off for all AC only after TXOP (as configured in ACM_EDCA_TXOP_AC[n]) expires if last transmission fails.;OPTIONAL: Must be left at default
  [n+4] MEM_CFG_AC{n}_ENABLE rw (n=0..5) — Enable AC for transmission
  [0] MEM_CFG_EDCA_EN rw — EDCA enable: enable EDCA functionality
0x378 acm_ifs_cfg0 reset 0x190190 — SIFS Count (ACM_IFS_CFG0)
  [11:0] MEM_CFG_TXSIFS_CNT rw — Number of clock cycles in SIFS interval _ Radio RxTx turnaround time.
0x37C acm_ifs_cfg1 reset 0x4B04B0 — Slot time configuration (ACM_IFS_CFG1)
  [11:0] MEM_CFG_SLOT_CNT rw — Slot time size in pMAC clock cycles (60Mhz clock)
0x380 cca_busy ro — CCA Medium Busy (CCA_BUSY)
  [27:0] CCA_BUSY — Free running counter that counts the number of clock cycles with CCA_N from the PHY high (indicating busy). Cleared upon a read of CCA_BUSY_CLR.
0x384 cca_busy_clr access not given — CCA Medium Busy (CCA_BUSY_CLR)
  [27:0] CCA_BUSY_RDCL ro — Free running counter that counts the number of clock cycles with CCA_N from the PHY high (indicating busy). Cleared upon a read of CCA_BUSY_RDCL_CLR.
0x388 cca_idle ro — CCA Medium Idle (CCA_IDLE)
  [27:0] CCA_IDLE — Free running counter that counts the number of clock cycles with CCA_N from the PHY low (indicating idle). Cleared upon a read of CCA_IDLE_CLR.
0x38C cca_idle_clr access not given — CCA Medium Idle (CCA_IDLE_CLR)
  [27:0] CCA_IDLE_RDCL ro — Free running counter that counts the number of clock cycles with CCA_N from the PHY low (indicating idle). Cleared upon a read of CCA_IDLE_RDCL_CLR.
0x390 ccafall2rx_dly_timer reset 0x77 — delay from QUAL CCA fall.
  [3:0] MEM_CFG_CCAFALL2RX_DLY_YIMER rw — Start value for the counter that counts from QUAL CCA falling. this counter is used to decrement from the duration feild from the frame header to adjust for PHY internal delay.
0x394 cpu_ovride_cca — override signals from phy
  [4] MEM_ALL_PV_CLR rw — 0: all pv enabled. 1: mask all the PV status so they are all considered 0s.
  [3] MEM_QUAL_CCA_OVR_VAL rw — phy_plcp_valid override value
  [2] MEM_QUAL_CCA_OVR_EN rw — phy_plcp_valid override enable
  [1] MEM_PHY_CCA_OVR_VAL rw — phy_cca override value
  [0] MEM_PHY_CCA_OVR_EN rw — phy_cca override enable
0x398 nav_update_cfg reset 0xC (reset mask 0xFFFFFFFC) — NAV Update Policy Configuration (NAV_UPDATE_CFG)
  [1] MEM_UPDATE_NAV_RTS_EN rw, [0] MEM_UPDATE_NAV_STOMP_POLICY_EN rw
0x39C acm_edca_status_reg ro — EDCA status (ACM_EDCA_STATUS_REG)
  [4n+3:4n] INTERNAL_COLLISION_AC{n} (n=0..5) — Internal collision count for AC{n}. Get cleared when AC{n} wins
0x3A0 acm_post_cnxt_ld_time_reg reset 0x320190 — Post context load time (ACM_POST_CNXT_LD_TIME _REG)
  [12:0] MEM_CFG_POST_BACKOFF_TIMER rw — This timer start when back-off goes to 0. At backoff 0. context get loaded to PANG. At the expiry of this counter a transmit strobe is generated
0x3A4 rx_timeout_cnt access not given — RX timeout counter
  [7:0] RX_TOUT_DOWN_CNT ro — RX timeout counter status in usec
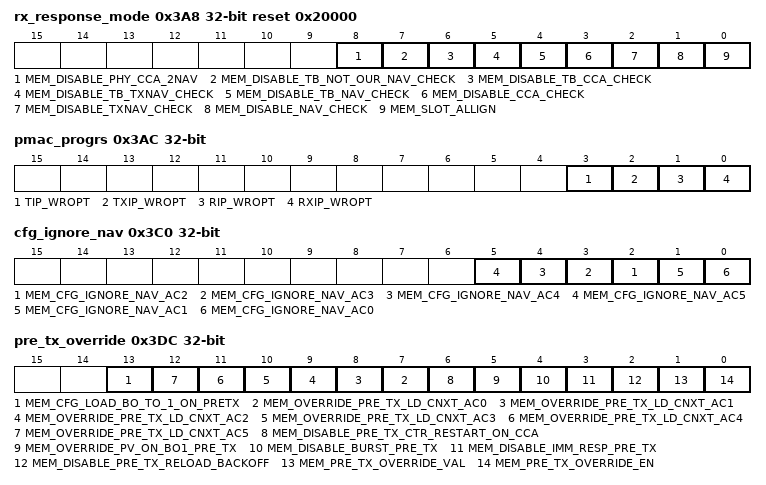
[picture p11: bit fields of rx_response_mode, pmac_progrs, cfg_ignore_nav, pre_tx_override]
0x3A8 rx_response_mode reset 0x20000 (reset mask 0xFFFFFE00) — Controls the option of the response frame timing
  [8] MEM_DISABLE_PHY_CCA_2NAV rw — Disable check of phy_cca to 'not_our_nav' One of the conditions to block TB response in addition to the 'cs_req' and NAV !=0, is that the air is cleared (this is from the 802.11 spec). If this bit is '1' - TB response is not depended on the phy_cca indication.
  [7] MEM_DISABLE_TB_NOT_OUR_NAV_CHECK rw — 0:NAV !=0 holds TB tx2rx delay count 1: Ignore Not-Our NAV output
  [6] MEM_DISABLE_TB_CCA_CHECK rw — 0:cca assertion holds TB tx2rx delay count
  [5] MEM_DISABLE_TB_TXNAV_CHECK rw — 0:txnav!=0 holds TB tx2rx delay count
  [4] MEM_DISABLE_TB_NAV_CHECK rw — 0:NAV !=0 holds TB tx2rx delay count
  [3] MEM_DISABLE_CCA_CHECK rw — 0:cca assertion holds tx2rx delay count
  [2] MEM_DISABLE_TXNAV_CHECK rw — 0:txnav!=0 holds tx2rx delay count
  [1] MEM_DISABLE_NAV_CHECK rw — 0:NAV !=0 holds tx2rx delay count
  [0] MEM_SLOT_ALLIGN rw — 1: the response frame is slot sligned (after rx2tx delay has passed from cca negation)
0x3AC pmac_progrs
  [3] TIP_WROPT rw — 1: from tx_start trigger untill the last I/Q
  [2] TXIP_WROPT rw — 1: from the end of transmission (when there is response ecpected), untill the response arrives or timeout
  [1] RIP_WROPT rw — 1: when the flexible parser is not in IDLE
  [0] RXIP_WROPT rw — 1: from rx response trigger (asserted by RX parser) untill tx_start
0x3B0 rx_start_time_latch ro — This register latch the time at the begining of plcp header (based on cfg in RX_TIME_LATCH_CTRL register
  [31:0] RX_START_LATCH — see above
0x3B4 rx_end_time_latch ro — This register latch the time at rx complete interrupt (based on cfg in RX_TIME_LATCH_CTRL register
  [31:0] RX_END_LATCH — see above
0x3B8 tsf_update_value_low rw — When writing this register, the TSF counter is update by TSF + {TSF_UPDATE_VALUE_HIGH , TSF_UPDATE_VALUE_LOW}. So the TSF HIGH should be updated first
  [31:0] TSF_UPDATE_VALUE_LOW_WROPT — LOW 32 bit of the STF update value
0x3BC tsf_update_value_high rw
  [31:0] MEM_TSF_UPDATE_VALUE_HIGH — HIGH 32 bit of the STF update value
0x3C0 cfg_ignore_nav — Ignore NAV is zero indication on medium access backoff counters
  [n] MEM_CFG_IGNORE_NAV_AC{n} rw (n=2..5) — ignore NAV is zero indication for AC{n} backoff
  [1] MEM_CFG_IGNORE_NAV_AC1 rw — ignore NAV is zero indication for AC0 backoff
  [0] MEM_CFG_IGNORE_NAV_AC0 rw — ignore NAV is zero indication for AC0 backoff
0x3C4 latched_tsf_tx_start_low ro — The value of TSF on TX trigger pulse. (lower 32bits)
  [31:0] TSF_ON_TX_TRIGGER_31TO0
0x3C8 latched_tsf_tx_start_high ro — The value of TSF on TX trigger pulse. (higher 32bits)
  [31:0] TSF_ON_TX_TRIGGER_63TO32
0x3CC tx_julutime_low ro — Latches TSF[31:0] on tx start.
0x3D0 tx_julutime_high ro — latches usec_offset on tx start. usec_offset is 6 bits counter on 40MHz. Cleared to 0 on usec_stb
  [5:0] TX_JULUTIME_HIGH
0x3D4 rx_julutime_low ro — Latches TSF[31:0] on plcp header rise
0x3D8 rx_julutime_high ro — latches usec_offset on plcp header rise. usec_offset is 6 bits counter on 40MHz. Cleared to 0 on usec_stb
  [5:0] RX_JULUTIME_HIGH
0x3DC pre_tx_override — override options for pre_tx logic
  [13] MEM_CFG_LOAD_BO_TO_1_ON_PRETX rw — when set, on cases where pre_tx caused Tx to be aborted, the Backoff counter will be loaded to 1. when cleared, a new backoff value is used.
  [n+7] MEM_OVERRIDE_PRE_TX_LD_CNXT_AC{n} rw (n=0..5) — when set, this ac will not trigger the pre_tx when its BO reaches value of 1
  [6] MEM_DISABLE_PRE_TX_CTR_RESTART_ON_CCA rw — when set, pre_tx will be asserted once if any AC reached backoff of 1. when cleared, pre_tx is asserted on every AC reaching backof of 1
  [5] MEM_OVERRIDE_PV_ON_BO1_PRE_TX rw — when set, pre_tx will be asserted when an AC reached BO of 1 regardless of pv PG1.0 - field return 0 on read
  [4] MEM_DISABLE_BURST_PRE_TX rw — disable the tx burst from triggering pre_tx logic
  [3] MEM_DISABLE_IMM_RESP_PRE_TX rw — disable only the imm_resp from triggering pre_tx
  [2] MEM_DISABLE_PRE_TX_RELOAD_BACKOFF rw — prevent from backoff counter from being reloaded to '1' on reaching 0 (return to legacy logic)
  [1] MEM_PRE_TX_OVERRIDE_VAL rw — the override value to be used - 0:pre_tx is held low 1: pre_tx is asserted
  [0] MEM_PRE_TX_OVERRIDE_EN rw — override the pre_tx signal entirely. when set, override value is taken from bit[1]
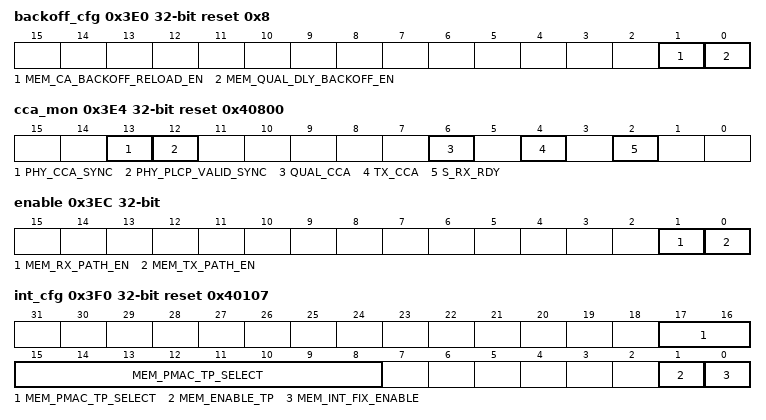
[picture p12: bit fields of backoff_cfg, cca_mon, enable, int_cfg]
0x3E0 backoff_cfg reset 0x8 (reset mask 0xFFFFFFFC) — Backoff Correction Congifuration (BACKOFF_CFG)
  [1] MEM_CA_BACKOFF_RELOAD_EN rw
    1=Enable Backoff_timer reload for Collision Avoidance. ;When Tx_CCA is high but Qual_CCA is low and the counter reaches a value of 1. reload the counter with the copy_backoff_timer value.;Enabled only if INT_CFG bit 0 is set;;0: Disable reload of this timer on reaching a value of 1. ;When Tx_CCA is high but Qual_CCA is low and the counter reaches a value of 1. freeze the counter and donot reload.
  [0] MEM_QUAL_DLY_BACKOFF_EN rw
    1=Enable Backoff_timer reload on Qual_CCA. ;When Qual_CCA goes high. reload the counter with the copy_backoff_timer value that was copied when Input_CCA went high.;Enabled only if INT_CFG bit 0 is set;;0: Disable reload of this timer on Qual_CCA. .
0x3E4 cca_mon ro reset 0x40800 (reset mask 0xFFFFCF80) — CPU CCA Register (CCA_MON)
  [13] PHY_CCA_SYNC — synched phy_cca, no override applied
  [12] PHY_PLCP_VALID_SYNC — synched input. no override applied
  [6] QUAL_CCA — Value of Qual_CCA signal from Access Manager. include override
  [4] TX_CCA — Value of TX_CCA from Access Manager before MAC qualification for gating transmits
  [2] S_RX_RDY — phy_hdr_start_stb
0x3E8 delay_cfg — Probe Delay Register (DELAY_CFG)
  [9:0] MEM_CFG_PRB_DLY rw — Number of microseconds to wait after tx_path_en is asserted
0x3EC enable — ENABLE Register (ENABLE)
  [1] MEM_RX_PATH_EN rw
    1=enable MAC receive interface. Rising edge causes receive interface to look for next start of frame on baseband receive interface.;0 = disable MAC receive interface. Falling edge causes Receive Manager to abort frame in progress. If it has written a partial frame to memory then it will interrupt and report appropriate status. and ignore the baseband receive interface.;Must be active for OFDM frames;(rx_path_en)
  [0] MEM_TX_PATH_EN rw
    1=enables Access Manager and Transmit Manager operation.;Must be de-asserted when changing radio channels.;0 = disable Access Manager and Transmit Manager;must be active for OFDM frames;(tx_path_en)
0x3F0 int_cfg reset 0x40107 — Inteference Avoidance Congifuration (INT_CFG) (WL8 Changes)
  [17:8] MEM_PMAC_TP_SELECT rw — selects the specific test port to be sent to the top from the PMAC after one 160 free clock pipe bits [4:0] indicates the PMAC test port selected till Ocla trigger bits [9:5] indicates the PMAC test port selected after Ocla trigger
  [1] MEM_ENABLE_TP rw — Enables the usage of the pMAC test ports. while this bit is disabled all test ports outputs are zeros. (for power saving) ********************************* NOTE ************************** to enable usage of debug ports please set this bit to 1 ********************************* NOTE **************************
  [0] MEM_INT_FIX_ENABLE rw
0x3F4 mac_timestamp rw — MAC Time Stamp (MAC_TIMESTAMP)
  [31:0] MAC_TIMESTAMP_WROPT — MAC timestamp based on usecs
0x3F8 tx_trigger_based_enable reset 0x3 — Enable Configuration Set 1 - Enable TX Trigger based winners. Set 0 - Disable TX Trigger based winners.
  [0] MEM_TX_TB_EN rw
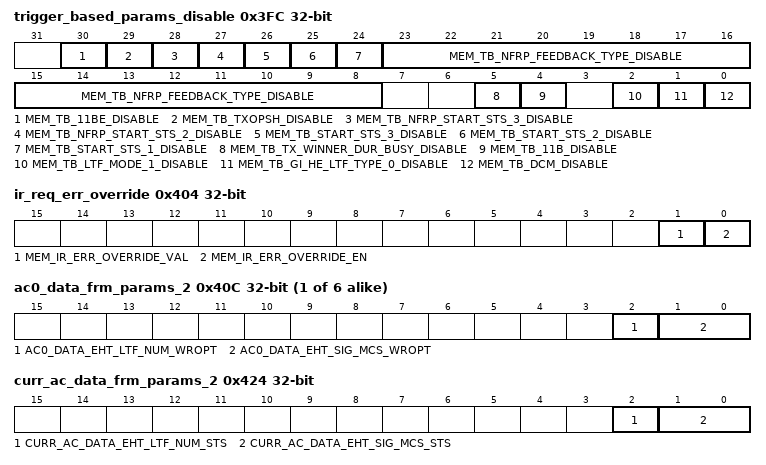
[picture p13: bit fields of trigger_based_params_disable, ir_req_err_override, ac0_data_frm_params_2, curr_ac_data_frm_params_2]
0x3FC trigger_based_params_disable reset not defined
  [30] MEM_TB_11BE_DISABLE rw — Added for Osprey-MDB-PG1: Option to block BE (= EHT=WiFi7) TB packet.
  [29] MEM_TB_TXOPSH_DISABLE rw — EHT TXOP-Sharing Disable option
  [28] MEM_TB_NFRP_START_STS_3_DISABLE rw
  [27] MEM_TB_NFRP_START_STS_2_DISABLE rw
  [26] MEM_TB_START_STS_3_DISABLE rw
  [25] MEM_TB_START_STS_2_DISABLE rw
  [24] MEM_TB_START_STS_1_DISABLE rw
  [23:8] MEM_TB_NFRP_FEEDBACK_TYPE_DISABLE rw
  [5] MEM_TB_TX_WINNER_DUR_BUSY_DISABLE rw — Added for Osprey-LSB-PG2 0: Not Disable TB-TX-Winner during Busy as exchange (as Legacy PG1) 1: Disable TB-TX-Winner during Busy as exchange (Default for LSB-PG2)
  [4] MEM_TB_11B_DISABLE rw — Added for Osprey-LSB-PG2
  [2] MEM_TB_LTF_MODE_1_DISABLE rw
  [1] MEM_TB_GI_HE_LTF_TYPE_0_DISABLE rw
  [0] MEM_TB_DCM_DISABLE rw
0x400 ir_err_req_status ro reset not defined
  [0] IR_ERR_RDCL — IR request error.
0x404 ir_req_err_override reset not defined
  [1] MEM_IR_ERR_OVERRIDE_VAL rw — Override value for IR request error decision.
  [0] MEM_IR_ERR_OVERRIDE_EN rw — Bypass HW error decision for IR request. The override value is set by MEM_IR_ERR_OVERRIDE_VAL register
0x408 tb_mu_rts_params_check_en reset not defined
  [0] MEM_TB_MU_RTS_RU_ALLOC_CHECK_EN rw
{0x40C+4i} ac{i}_data_frm_params_2 (i=0..5) — current data frame params as set by the tx candidate.
  [2] AC{i}_DATA_EHT_LTF_NUM_WROPT rw, [1:0] AC{i}_DATA_EHT_SIG_MCS_WROPT rw
0x424 curr_ac_data_frm_params_2 ro — current data frame params as set by the tx candidate.
  [2] CURR_AC_DATA_EHT_LTF_NUM_STS, [1:0] CURR_AC_DATA_EHT_SIG_MCS_STS
